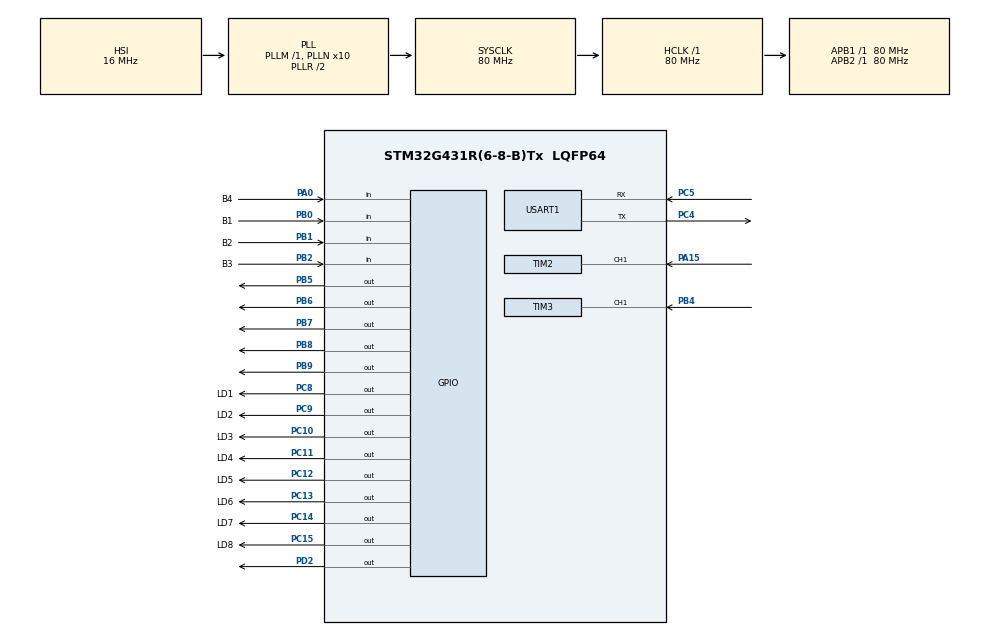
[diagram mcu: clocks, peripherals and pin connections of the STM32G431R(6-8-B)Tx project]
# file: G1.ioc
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Mcu.Family=STM32G4
Mcu.Name=STM32G431R(6-8-B)Tx
Mcu.Package=LQFP64
NVIC.PriorityGroup=NVIC_PRIORITYGROUP_3
NVIC.TIM2_IRQn=true\:1\:0\:true\:false\:true\:true\:true\:true
NVIC.TIM3_IRQn=true\:1\:0\:true\:false\:true\:true\:true\:true
NVIC.TIM6_DAC_IRQn=true\:0\:0\:false\:false\:true\:true\:true\:true
PA0.GPIO_Label=B4
PA0.Signal=GPIO_Input
PA13.Mode=Serial_Wire
PA13.Signal=SYS_JTMS-SWDIO
PA14.Mode=Serial_Wire
PA14.Signal=SYS_JTCK-SWCLK
PA15.Signal=S_TIM2_CH1
PB0.GPIO_Label=B1
PB0.Signal=GPIO_Input
PB1.GPIO_Label=B2
PB1.Signal=GPIO_Input
PB2.GPIO_Label=B3
PB2.Signal=GPIO_Input
PB4.Signal=S_TIM3_CH1
PB5.Signal=GPIO_Output
PB6.Signal=GPIO_Output
PB7.Signal=GPIO_Output
PB8-BOOT0.Signal=GPIO_Output
PB9.Signal=GPIO_Output
PC10.GPIO_Label=LD3
PC10.Signal=GPIO_Output
PC11.GPIO_Label=LD4
PC11.Signal=GPIO_Output
PC12.GPIO_Label=LD5
PC12.Signal=GPIO_Output
PC13.GPIO_Label=LD6
PC13.Signal=GPIO_Output
PC14-OSC32_IN.GPIO_Label=LD7
PC14-OSC32_IN.Signal=GPIO_Output
PC15-OSC32_OUT.GPIO_Label=LD8
PC15-OSC32_OUT.Signal=GPIO_Output
PC4.Mode=Asynchronous
PC4.Signal=USART1_TX
PC5.Mode=Asynchronous
PC5.Signal=USART1_RX
PC8.GPIO_Label=LD1
PC8.Signal=GPIO_Output
PC9.GPIO_Label=LD2
PC9.Signal=GPIO_Output
PD2.Signal=GPIO_Output
PF0-OSC_IN.Mode=HSE-External-Oscillator
PF0-OSC_IN.Signal=RCC_OSC_IN
PF1-OSC_OUT.Mode=HSE-External-Oscillator
PF1-OSC_OUT.Signal=RCC_OSC_OUT
ProjectManager.HeapSize=0x200
ProjectManager.StackSize=0x400
ProjectManager.TargetToolchain=MDK-ARM V5.32
RCC.ADC12Freq_Value=80000000
RCC.AHBFreq_Value=80000000
RCC.APB1Freq_Value=80000000
RCC.APB1TimFreq_Value=80000000
RCC.APB2Freq_Value=80000000
RCC.APB2TimFreq_Value=80000000
RCC.CortexFreq_Value=80000000
RCC.EXTERNAL_CLOCK_VALUE=12288000
RCC.HCLKFreq_Value=80000000
RCC.HSE_VALUE=24000000
RCC.HSI48_VALUE=48000000
RCC.HSI_VALUE=16000000
RCC.LSE_VALUE=32768
RCC.PLLN=10
RCC.SYSCLKFreq_VALUE=80000000
RCC.SYSCLKSource=RCC_SYSCLKSOURCE_PLLCLK
RCC.USBFreq_Value=80000000
RCC.VCOOutputFreq_Value=160000000
SH.S_TIM2_CH1.0=TIM2_CH1,Input_Capture1_from_TI1
SH.S_TIM3_CH1.0=TIM3_CH1,Input_Capture1_from_TI1
TIM2.Channel-Input_Capture1_from_TI1=TIM_CHANNEL_1
TIM2.Prescaler=799
TIM3.Channel-Input_Capture1_from_TI1=TIM_CHANNEL_1
TIM3.Prescaler=799
TIM6.PeriodNoDither=24999
TIM6.Prescaler=799
USART1.VirtualMode-Asynchronous=VM_ASYNC
VP_SYS_VS_DBSignals.Mode=DisableDeadBatterySignals
VP_TIM6_VS_ClockSourceINT.Mode=Enable_Timer
board=custom

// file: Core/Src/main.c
/* USER CODE BEGIN Header */
/**
 ******************************************************************************
 * @file           : main.c
 * @brief          : Main program body
 ******************************************************************************
 * @attention
 *
 * Copyright (c) 2024 STMicroelectronics.
 * All rights reserved.
 *
 * This software is licensed under terms that can be found in the LICENSE file
 * in the root directory of this software component.
 * If no LICENSE file comes with this software, it is provided AS-IS.
 *
 ******************************************************************************
 */
/* USER CODE END Header */
#include "main.h"

/* USER CODE BEGIN Includes */
#include "lcd.h"
#include "user.h"
/* USER CODE END Includes */

TIM_HandleTypeDef htim2;
TIM_HandleTypeDef htim3;
TIM_HandleTypeDef htim6;

UART_HandleTypeDef huart1;

void SystemClock_Config(void);
static void MX_GPIO_Init(void);
static void MX_TIM2_Init(void);
static void MX_TIM3_Init(void);
static void MX_TIM6_Init(void);
static void MX_USART1_UART_Init(void);

int main(void)
{

  /* MCU Configuration--------------------------------------------------------*/

  /* Reset of all peripherals, Initializes the Flash interface and the Systick. */
  HAL_Init();

  /* Configure the system clock */
  SystemClock_Config();

  /* Initialize all configured peripherals */
  MX_GPIO_Init();
  MX_TIM2_Init();
  MX_TIM3_Init();
  MX_TIM6_Init();
  MX_USART1_UART_Init();

  /* Infinite loop */
  /* USER CODE BEGIN WHILE */
    HAL_TIM_IC_Start_IT(&htim2,TIM_CHANNEL_1);
    HAL_TIM_IC_Start_IT(&htim3,TIM_CHANNEL_1);
    HAL_TIM_Base_Start_IT(&htim6);
    LCD_Init();
    LCD_SetTextColor(White);
    LCD_SetBackColor(Black);
    LCD_Clear(Black);
    Fresh();
    HAL_Delay(100);
    while (1) {
        ScanKey();
    /* USER CODE END WHILE */

    }
}

void SystemClock_Config(void)
{
  RCC_OscInitTypeDef RCC_OscInitStruct = {0};
  RCC_ClkInitTypeDef RCC_ClkInitStruct = {0};

  /** Configure the main internal regulator output voltage
  */
  HAL_PWREx_ControlVoltageScaling(PWR_REGULATOR_VOLTAGE_SCALE1);

  /** Initializes the RCC Oscillators according to the specified parameters
  * in the RCC_OscInitTypeDef structure.
  */
  RCC_OscInitStruct.OscillatorType = RCC_OSCILLATORTYPE_HSI;
  RCC_OscInitStruct.HSIState = RCC_HSI_ON;
  RCC_OscInitStruct.HSICalibrationValue = RCC_HSICALIBRATION_DEFAULT;
  RCC_OscInitStruct.PLL.PLLState = RCC_PLL_ON;
  RCC_OscInitStruct.PLL.PLLSource = RCC_PLLSOURCE_HSI;
  RCC_OscInitStruct.PLL.PLLM = RCC_PLLM_DIV1;
  RCC_OscInitStruct.PLL.PLLN = 10;
  RCC_OscInitStruct.PLL.PLLP = RCC_PLLP_DIV2;
  RCC_OscInitStruct.PLL.PLLQ = RCC_PLLQ_DIV2;
  RCC_OscInitStruct.PLL.PLLR = RCC_PLLR_DIV2;
  if (HAL_RCC_OscConfig(&RCC_OscInitStruct) != HAL_OK)
  {
    Error_Handler();
  }

  /** Initializes the CPU, AHB and APB buses clocks
  */
  RCC_ClkInitStruct.ClockType = RCC_CLOCKTYPE_HCLK|RCC_CLOCKTYPE_SYSCLK
                              |RCC_CLOCKTYPE_PCLK1|RCC_CLOCKTYPE_PCLK2;
  RCC_ClkInitStruct.SYSCLKSource = RCC_SYSCLKSOURCE_PLLCLK;
  RCC_ClkInitStruct.AHBCLKDivider = RCC_SYSCLK_DIV1;
  RCC_ClkInitStruct.APB1CLKDivider = RCC_HCLK_DIV1;
  RCC_ClkInitStruct.APB2CLKDivider = RCC_HCLK_DIV1;

  if (HAL_RCC_ClockConfig(&RCC_ClkInitStruct, FLASH_LATENCY_2) != HAL_OK)
  {
    Error_Handler();
  }
}

static void MX_TIM2_Init(void)
{

  TIM_MasterConfigTypeDef sMasterConfig = {0};
  TIM_IC_InitTypeDef sConfigIC = {0};

  htim2.Instance = TIM2;
  htim2.Init.Prescaler = 799;
  htim2.Init.CounterMode = TIM_COUNTERMODE_UP;
  htim2.Init.Period = 4294967295;
  htim2.Init.ClockDivision = TIM_CLOCKDIVISION_DIV1;
  htim2.Init.AutoReloadPreload = TIM_AUTORELOAD_PRELOAD_DISABLE;
  if (HAL_TIM_IC_Init(&htim2) != HAL_OK)
  {
    Error_Handler();
  }
  sMasterConfig.MasterOutputTrigger = TIM_TRGO_RESET;
  sMasterConfig.MasterSlaveMode = TIM_MASTERSLAVEMODE_DISABLE;
  if (HAL_TIMEx_MasterConfigSynchronization(&htim2, &sMasterConfig) != HAL_OK)
  {
    Error_Handler();
  }
  sConfigIC.ICPolarity = TIM_INPUTCHANNELPOLARITY_RISING;
  sConfigIC.ICSelection = TIM_ICSELECTION_DIRECTTI;
  sConfigIC.ICPrescaler = TIM_ICPSC_DIV1;
  sConfigIC.ICFilter = 0;
  if (HAL_TIM_IC_ConfigChannel(&htim2, &sConfigIC, TIM_CHANNEL_1) != HAL_OK)
  {
    Error_Handler();
  }

}

static void MX_TIM3_Init(void)
{

  TIM_MasterConfigTypeDef sMasterConfig = {0};
  TIM_IC_InitTypeDef sConfigIC = {0};

  htim3.Instance = TIM3;
  htim3.Init.Prescaler = 799;
  htim3.Init.CounterMode = TIM_COUNTERMODE_UP;
  htim3.Init.Period = 65535;
  htim3.Init.ClockDivision = TIM_CLOCKDIVISION_DIV1;
  htim3.Init.AutoReloadPreload = TIM_AUTORELOAD_PRELOAD_DISABLE;
  if (HAL_TIM_IC_Init(&htim3) != HAL_OK)
  {
    Error_Handler();
  }
  sMasterConfig.MasterOutputTrigger = TIM_TRGO_RESET;
  sMasterConfig.MasterSlaveMode = TIM_MASTERSLAVEMODE_DISABLE;
  if (HAL_TIMEx_MasterConfigSynchronization(&htim3, &sMasterConfig) != HAL_OK)
  {
    Error_Handler();
  }
  sConfigIC.ICPolarity = TIM_INPUTCHANNELPOLARITY_RISING;
  sConfigIC.ICSelection = TIM_ICSELECTION_DIRECTTI;
  sConfigIC.ICPrescaler = TIM_ICPSC_DIV1;
  sConfigIC.ICFilter = 0;
  if (HAL_TIM_IC_ConfigChannel(&htim3, &sConfigIC, TIM_CHANNEL_1) != HAL_OK)
  {
    Error_Handler();
  }

}

static void MX_TIM6_Init(void)
{

  TIM_MasterConfigTypeDef sMasterConfig = {0};

  htim6.Instance = TIM6;
  htim6.Init.Prescaler = 799;
  htim6.Init.CounterMode = TIM_COUNTERMODE_UP;
  htim6.Init.Period = 24999;
  htim6.Init.AutoReloadPreload = TIM_AUTORELOAD_PRELOAD_DISABLE;
  if (HAL_TIM_Base_Init(&htim6) != HAL_OK)
  {
    Error_Handler();
  }
  sMasterConfig.MasterOutputTrigger = TIM_TRGO_RESET;
  sMasterConfig.MasterSlaveMode = TIM_MASTERSLAVEMODE_DISABLE;
  if (HAL_TIMEx_MasterConfigSynchronization(&htim6, &sMasterConfig) != HAL_OK)
  {
    Error_Handler();
  }

}

static void MX_USART1_UART_Init(void)
{

  huart1.Instance = USART1;
  huart1.Init.BaudRate = 115200;
  huart1.Init.WordLength = UART_WORDLENGTH_8B;
  huart1.Init.StopBits = UART_STOPBITS_1;
  huart1.Init.Parity = UART_PARITY_NONE;
  huart1.Init.Mode = UART_MODE_TX_RX;
  huart1.Init.HwFlowCtl = UART_HWCONTROL_NONE;
  huart1.Init.OverSampling = UART_OVERSAMPLING_16;
  huart1.Init.OneBitSampling = UART_ONE_BIT_SAMPLE_DISABLE;
  huart1.Init.ClockPrescaler = UART_PRESCALER_DIV1;
  huart1.AdvancedInit.AdvFeatureInit = UART_ADVFEATURE_NO_INIT;
  if (HAL_UART_Init(&huart1) != HAL_OK)
  {
    Error_Handler();
  }
  if (HAL_UARTEx_SetTxFifoThreshold(&huart1, UART_TXFIFO_THRESHOLD_1_8) != HAL_OK)
  {
    Error_Handler();
  }
  if (HAL_UARTEx_SetRxFifoThreshold(&huart1, UART_RXFIFO_THRESHOLD_1_8) != HAL_OK)
  {
    Error_Handler();
  }
  if (HAL_UARTEx_DisableFifoMode(&huart1) != HAL_OK)
  {
    Error_Handler();
  }

}

static void MX_GPIO_Init(void)
{
  GPIO_InitTypeDef GPIO_InitStruct = {0};

  /* GPIO Ports Clock Enable */
  __HAL_RCC_GPIOC_CLK_ENABLE();
  __HAL_RCC_GPIOF_CLK_ENABLE();
  __HAL_RCC_GPIOA_CLK_ENABLE();
  __HAL_RCC_GPIOB_CLK_ENABLE();
  __HAL_RCC_GPIOD_CLK_ENABLE();

  /*Configure GPIO pin Output Level */
  HAL_GPIO_WritePin(GPIOC, LD6_Pin|LD7_Pin|LD8_Pin|LD1_Pin
                          |LD2_Pin|LD3_Pin|LD4_Pin|LD5_Pin, GPIO_PIN_RESET);

  /*Configure GPIO pin Output Level */
  HAL_GPIO_WritePin(GPIOD, GPIO_PIN_2, GPIO_PIN_RESET);

  /*Configure GPIO pin Output Level */
  HAL_GPIO_WritePin(GPIOB, GPIO_PIN_5|GPIO_PIN_6|GPIO_PIN_7|GPIO_PIN_8
                          |GPIO_PIN_9, GPIO_PIN_RESET);

  /*Configure GPIO pins : LD6_Pin LD7_Pin LD8_Pin LD1_Pin
                           LD2_Pin LD3_Pin LD4_Pin LD5_Pin */
  GPIO_InitStruct.Pin = LD6_Pin|LD7_Pin|LD8_Pin|LD1_Pin
                          |LD2_Pin|LD3_Pin|LD4_Pin|LD5_Pin;
  GPIO_InitStruct.Mode = GPIO_MODE_OUTPUT_PP;
  GPIO_InitStruct.Pull = GPIO_NOPULL;
  GPIO_InitStruct.Speed = GPIO_SPEED_FREQ_LOW;
  HAL_GPIO_Init(GPIOC, &GPIO_InitStruct);

  /*Configure GPIO pin : B4_Pin */
  GPIO_InitStruct.Pin = B4_Pin;
  GPIO_InitStruct.Mode = GPIO_MODE_INPUT;
  GPIO_InitStruct.Pull = GPIO_NOPULL;
  HAL_GPIO_Init(B4_GPIO_Port, &GPIO_InitStruct);

  /*Configure GPIO pins : B1_Pin B2_Pin B3_Pin */
  GPIO_InitStruct.Pin = B1_Pin|B2_Pin|B3_Pin;
  GPIO_InitStruct.Mode = GPIO_MODE_INPUT;
  GPIO_InitStruct.Pull = GPIO_NOPULL;
  HAL_GPIO_Init(GPIOB, &GPIO_InitStruct);

  /*Configure GPIO pin : PD2 */
  GPIO_InitStruct.Pin = GPIO_PIN_2;
  GPIO_InitStruct.Mode = GPIO_MODE_OUTPUT_PP;
  GPIO_InitStruct.Pull = GPIO_NOPULL;
  GPIO_InitStruct.Speed = GPIO_SPEED_FREQ_LOW;
  HAL_GPIO_Init(GPIOD, &GPIO_InitStruct);

  /*Configure GPIO pins : PB5 PB6 PB7 PB8
                           PB9 */
  GPIO_InitStruct.Pin = GPIO_PIN_5|GPIO_PIN_6|GPIO_PIN_7|GPIO_PIN_8
                          |GPIO_PIN_9;
  GPIO_InitStruct.Mode = GPIO_MODE_OUTPUT_PP;
  GPIO_InitStruct.Pull = GPIO_NOPULL;
  GPIO_InitStruct.Speed = GPIO_SPEED_FREQ_LOW;
  HAL_GPIO_Init(GPIOB, &GPIO_InitStruct);

}

void Error_Handler(void)
{
    __disable_irq();
    while (1) {
    }
}
